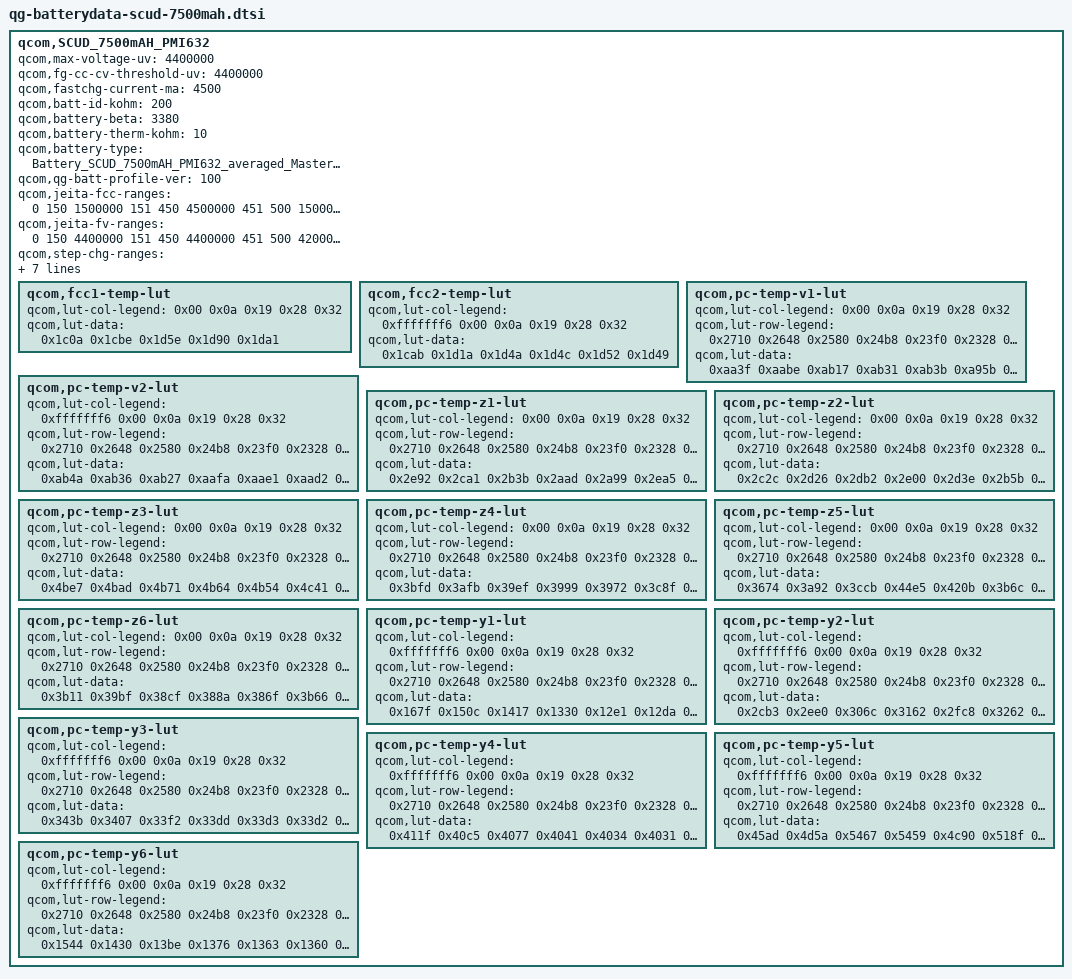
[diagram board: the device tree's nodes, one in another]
qcom,SCUD_7500mAH_PMI632 {
	qcom,max-voltage-uv = <4400000>;
	qcom,fg-cc-cv-threshold-uv = <4400000>;
	qcom,fastchg-current-ma = <4500>;
	qcom,batt-id-kohm = <200>;
	qcom,battery-beta = <3380>;
	qcom,battery-therm-kohm = <10>;
	qcom,battery-type = "Battery_SCUD_7500mAH_PMI632_averaged_MasterSlave_Jul21th2020";
	qcom,qg-batt-profile-ver = <100>;
	qcom,jeita-fcc-ranges = <0 150 1500000 151 450 4500000 451 500 1500000>;
	qcom,jeita-fv-ranges = <0 150 4400000 151 450 4400000 451 500 4200000>;
	qcom,step-chg-ranges = <3600000 3800000 4500000 3800001 4300000 4500000 4300001 4400000 2500000>;
	qcom,ocv-based-step-chg;
	qcom,jeita-soft-thresholds = <9556 4060>;
	qcom,jeita-hard-thresholds = <22733 8376>;
	qcom,jeita-soft-hys-thresholds = <20318 10563>;
	qcom,jeita-soft-fcc-ua = <4500000 4500000>;
	qcom,jeita-soft-fv-uv = <4400000 4400000>;

	qcom,fcc1-temp-lut {
		qcom,lut-col-legend = <0x00 0x0a 0x19 0x28 0x32>;
		qcom,lut-data = <0x1c0a 0x1cbe 0x1d5e 0x1d90 0x1da1>;
	};

	qcom,fcc2-temp-lut {
		qcom,lut-col-legend = <0xfffffff6 0x00 0x0a 0x19 0x28 0x32>;
		qcom,lut-data = <0x1cab 0x1d1a 0x1d4a 0x1d4c 0x1d52 0x1d49>;
	};

	qcom,pc-temp-v1-lut {
		qcom,lut-col-legend = <0x00 0x0a 0x19 0x28 0x32>;
		qcom,lut-row-legend = <0x2710 0x2648 0x2580 0x24b8 0x23f0 0x2328 0x2260 0x2198 0x20d0 0x2008 0x1f40 0x1e78 0x1db0 0x1ce8 0x1c20 0x1b58 0x1a90 0x19c8 0x1900 0x1838 0x1770 0x16a8 0x15e0 0x1518 0x1450 0x1388 0x12c0 0x11f8 0x1130 0x1068 0xfa0 0xed8 0xe10 0xd48 0xc80 0xbb8 0xaf0 0xa28 0x960 0x898 0x7d0 0x708 0x640 0x578 0x4b0 0x3e8 0x384 0x320 0x2bc 0x258 0x1f4 0x190 0x12c 0xc8 0x64 0x00>;
		qcom,lut-data = <0xaa3f 0xaabe 0xab17 0xab31 0xab3b 0xa95b 0xa9db 0xaa47 0xaa5d 0xaa67 0xa86b 0xa8f6 0xa960 0xa97f 0xa98b 0xa77c 0xa80e 0xa878 0xa89d 0xa8ad 0xa693 0xa726 0xa78c 0xa7b7 0xa7cb 0xa5ab 0xa63a 0xa69f 0xa6cd 0xa6e5 0xa4c8 0xa550 0xa5b5 0xa5e3 0xa5fe 0xa3e9 0xa468 0xa4cb 0xa4f8 0xa516 0xa30e 0xa386 0xa3e4 0xa410 0xa42f 0xa238 0xa2a7 0xa2fd 0xa32c 0xa349 0xa166 0xa1ce 0xa21b 0xa24c 0xa266 0xa09c 0xa0f9 0xa142 0xa170 0xa189 0x9fdd 0xa02c 0xa06d 0xa096 0xa0b1 0x9f23 0x9f69 0x9fa0 0x9fc5 0x9fe0 0x9e63 0x9eab 0x9ed8 0x9efa 0x9f12 0x9d9d 0x9def 0x9e18 0x9e37 0x9e4c 0x9ce5 0x9d38 0x9d62 0x9d7d 0x9d90 0x9c48 0x9c8a 0x9cb3 0x9ccb 0x9cde 0x9bb8 0x9bea 0x9c0e 0x9c1f 0x9c31 0x9b26 0x9b51 0x9b78 0x9b82 0x9b8f 0x9a91 0x9ab1 0x9ad6 0x9ae0 0x9ae9 0x99fd 0x9a11 0x9a06 0x9a10 0x9a23 0x996c 0x9965 0x9920 0x991b 0x993f 0x98dd 0x9890 0x985f 0x985a 0x987f 0x9851 0x97b8 0x97b5 0x97d4 0x97f0 0x97c3 0x972d 0x972f 0x9764 0x9775 0x973e 0x96cf 0x96d8 0x96fb 0x9702 0x96d8 0x9683 0x9695 0x969b 0x9698 0x9687 0x9641 0x964e 0x9641 0x9639 0x9642 0x9607 0x9605 0x95eb 0x95e3 0x9609 0x95d3 0x95c1 0x959e 0x9596 0x95d8 0x95a1 0x9583 0x9558 0x954e 0x95ad 0x9573 0x954c 0x951a 0x950b 0x9588 0x9547 0x9519 0x94e2 0x94cd 0x9566 0x951e 0x94eb 0x94b1 0x9496 0x9545 0x94f6 0x94bf 0x9480 0x945e 0x9525 0x94d2 0x9496 0x944c 0x941e 0x94fd 0x94a9 0x946d 0x9415 0x93da 0x94c2 0x9469 0x9430 0x93d0 0x938d 0x9474 0x940d 0x93d4 0x9377 0x9333 0x9414 0x93a5 0x9369 0x9311 0x92ce 0x9394 0x932e 0x92f4 0x92a0 0x925c 0x9304 0x92a6 0x926f 0x921e 0x91d9 0x9263 0x9201 0x91cf 0x917e 0x913a 0x91cf 0x916f 0x913e 0x90f4 0x90b1 0x9157 0x910e 0x90e1 0x90a0 0x9061 0x9134 0x90f1 0x90cb 0x9089 0x904d 0x911c 0x90da 0x90b7 0x907b 0x903e 0x90fc 0x90c4 0x90a7 0x9069 0x902b 0x90d6 0x909e 0x907e 0x903a 0x8ff7 0x9075 0x8fea 0x8fa8 0x8f47 0x8eeb 0x8f20 0x8e3b 0x8dfe 0x8d98 0x8d39 0x8d11 0x8bfd 0x8bc6 0x8b60 0x8b00 0x8a43 0x88d5 0x88c3 0x885b 0x87fd 0x8568 0x83b0 0x8418 0x83b8 0x835b 0x7530 0x7530 0x7530 0x7530 0x7530>;
	};

	qcom,pc-temp-v2-lut {
		qcom,lut-col-legend = <0xfffffff6 0x00 0x0a 0x19 0x28 0x32>;
		qcom,lut-row-legend = <0x2710 0x2648 0x2580 0x24b8 0x23f0 0x2328 0x2260 0x2198 0x20d0 0x2008 0x1f40 0x1e78 0x1db0 0x1ce8 0x1c20 0x1b58 0x1a90 0x19c8 0x1900 0x1838 0x1770 0x16a8 0x15e0 0x1518 0x1450 0x1388 0x12c0 0x11f8 0x1130 0x1068 0xfa0 0xed8 0xe10 0xd48 0xc80 0xbb8 0xaf0 0xa28 0x960 0x898 0x7d0 0x708 0x640 0x578 0x4b0 0x3e8 0x384 0x320 0x2bc 0x258 0x1f4 0x190 0x12c 0xc8 0x64 0x00>;
		qcom,lut-data = <0xab4a 0xab36 0xab27 0xaafa 0xaae1 0xaad2 0xa9fc 0xaa11 0xaa1a 0xa9ea 0xa9dd 0xa9d2 0xa8ca 0xa8fd 0xa917 0xa8e5 0xa8e0 0xa8d9 0xa7b8 0xa7fb 0xa81f 0xa7ed 0xa7ee 0xa7e9 0xa6c6 0xa70b 0xa733 0xa702 0xa706 0xa703 0xa5dc 0xa620 0xa649 0xa619 0xa61e 0xa61e 0xa4ed 0xa532 0xa55e 0xa52e 0xa535 0xa535 0xa400 0xa446 0xa473 0xa443 0xa44b 0xa44d 0xa318 0xa361 0xa38c 0xa35d 0xa366 0xa368 0xa235 0xa281 0xa2a9 0xa279 0xa283 0xa287 0xa157 0xa1a6 0xa1c8 0xa199 0xa1a4 0xa1a8 0xa082 0xa0ce 0xa0ed 0xa0bf 0xa0cc 0xa0cf 0x9fb2 0x9ffa 0xa016 0x9fe8 0x9ff8 0x9ffa 0x9ed4 0x9f2c 0x9f46 0x9f1c 0x9f2b 0x9f2e 0x9dd6 0x9e63 0x9e7c 0x9e55 0x9e62 0x9e67 0x9cd6 0x9d93 0x9db6 0x9d96 0x9da1 0x9da7 0x9bf2 0x9cab 0x9cf7 0x9cdf 0x9ce9 0x9cef 0x9b1f 0x9bb8 0x9c38 0x9c2e 0x9c38 0x9c3e 0x9a56 0x9ad8 0x9b67 0x9b81 0x9b8e 0x9b92 0x9996 0x9a09 0x9a7b 0x9adc 0x9aec 0x9af0 0x98df 0x9949 0x999d 0x9a28 0x9a3d 0x9a41 0x9833 0x9894 0x98d7 0x993f 0x995d 0x9964 0x9793 0x97ec 0x9824 0x984b 0x9873 0x987d 0x96f8 0x9755 0x9788 0x979a 0x97c3 0x97cd 0x965c 0x96cf 0x96fe 0x9712 0x9735 0x9741 0x95c8 0x9654 0x9683 0x969c 0x96bb 0x96c7 0x9553 0x95e0 0x9616 0x9632 0x9650 0x965c 0x94f2 0x9573 0x95b3 0x95d1 0x95f0 0x95fb 0x94a2 0x950f 0x9558 0x957a 0x9599 0x95a1 0x9464 0x94ad 0x9503 0x952a 0x9548 0x954f 0x9430 0x945a 0x94b4 0x94e1 0x94ff 0x9503 0x93fd 0x9418 0x9469 0x949a 0x94bc 0x94bd 0x93cb 0x93e2 0x9422 0x9458 0x947d 0x947b 0x9399 0x93b5 0x93e1 0x9419 0x943d 0x9437 0x9363 0x9395 0x93a5 0x93e1 0x93fe 0x93f3 0x932a 0x9373 0x936f 0x93a5 0x93b6 0x93a4 0x92ec 0x934a 0x9344 0x9361 0x935c 0x933c 0x92a9 0x931a 0x931b 0x9317 0x92f9 0x92c6 0x9261 0x92e0 0x92e6 0x92ce 0x92a1 0x9264 0x9212 0x9299 0x92a1 0x9286 0x9251 0x9213 0x91bb 0x9243 0x924d 0x9235 0x91fa 0x91bd 0x9161 0x91cf 0x91e1 0x91d1 0x9192 0x9155 0x9107 0x913d 0x9160 0x915b 0x911c 0x90df 0x90ab 0x90a2 0x90c2 0x90c3 0x9086 0x9048 0x904f 0x9012 0x903f 0x9050 0x901f 0x8fe6 0x8ff1 0x8fb6 0x8ff7 0x9022 0x8ffa 0x8fc5 0x8fbf 0x8f93 0x8fdb 0x9012 0x8fed 0x8fb7 0x8f88 0x8f66 0x8fbf 0x9004 0x8fdf 0x8fa7 0x8f4b 0x8f2f 0x8f91 0x8fe7 0x8fc4 0x8f8c 0x8f00 0x8ed8 0x8f3a 0x8fac 0x8f80 0x8f3b 0x8ea7 0x8e23 0x8e54 0x8ec9 0x8e7f 0x8e1b 0x8e01 0x8cc6 0x8c73 0x8d07 0x8cac 0x8c45 0x8ce1 0x8a7e 0x89e4 0x8aac 0x8a4a 0x89dd 0x8b04 0x86ff 0x866d 0x877c 0x870a 0x8695 0x87f4 0x816c 0x8106 0x82bf 0x8211 0x818d 0x8254 0x78cf 0x72f6 0x7258 0x72c5 0x7305>;
	};

	qcom,pc-temp-z1-lut {
		qcom,lut-col-legend = <0x00 0x0a 0x19 0x28 0x32>;
		qcom,lut-row-legend = <0x2710 0x2648 0x2580 0x24b8 0x23f0 0x2328 0x2260 0x2198 0x20d0 0x2008 0x1f40 0x1e78 0x1db0 0x1ce8 0x1c20 0x1b58 0x1a90 0x19c8 0x1900 0x1838 0x1770 0x16a8 0x15e0 0x1518 0x1450 0x1388 0x12c0 0x11f8 0x1130 0x1068 0xfa0 0xed8 0xe10 0xd48 0xc80 0xbb8 0xaf0 0xa28 0x960 0x898 0x7d0 0x708 0x640 0x578 0x4b0 0x3e8 0x384 0x320 0x2bc 0x258 0x1f4 0x190 0x12c 0xc8 0x64 0x00>;
		qcom,lut-data = <0x2e92 0x2ca1 0x2b3b 0x2aad 0x2a99 0x2ea5 0x2cad 0x2b35 0x2abd 0x2aad 0x2ea4 0x2cae 0x2b3b 0x2ac0 0x2ab2 0x2ea0 0x2caa 0x2b3c 0x2ac0 0x2ab6 0x2e90 0x2ca3 0x2b3b 0x2ac1 0x2ab7 0x2e79 0x2c9c 0x2b3a 0x2ac2 0x2ab8 0x2e71 0x2c92 0x2b38 0x2ac3 0x2ab9 0x2e71 0x2c8c 0x2b34 0x2ac3 0x2abc 0x2e72 0x2c86 0x2b33 0x2ac4 0x2abe 0x2e6a 0x2c81 0x2b34 0x2ac6 0x2ac0 0x2e5a 0x2c81 0x2b36 0x2ac8 0x2ac1 0x2e4f 0x2c82 0x2b36 0x2ac9 0x2ac2 0x2e4a 0x2c81 0x2b37 0x2ac9 0x2ac1 0x2e45 0x2c7f 0x2b37 0x2ac9 0x2ac1 0x2e40 0x2c7c 0x2b38 0x2aca 0x2ac3 0x2e3a 0x2c7a 0x2b39 0x2acc 0x2ac4 0x2e33 0x2c79 0x2b3a 0x2acc 0x2ac5 0x2e27 0x2c78 0x2b3b 0x2aca 0x2ac6 0x2e1a 0x2c7c 0x2b3d 0x2aca 0x2ac7 0x2e17 0x2c83 0x2b3f 0x2acc 0x2ac8 0x2e20 0x2c87 0x2b42 0x2ace 0x2aca 0x2e2a 0x2c8a 0x2b45 0x2ad0 0x2acb 0x2e2f 0x2c8c 0x2b47 0x2ad2 0x2acc 0x2e33 0x2c8e 0x2b4a 0x2ad3 0x2acd 0x2e37 0x2c91 0x2b4d 0x2ad5 0x2acf 0x2e34 0x2c92 0x2b51 0x2ad8 0x2ad2 0x2e2f 0x2c94 0x2b53 0x2ada 0x2ad4 0x2e32 0x2c95 0x2b56 0x2add 0x2ad6 0x2e3a 0x2c97 0x2b5a 0x2adf 0x2ad7 0x2e40 0x2c99 0x2b5d 0x2ae1 0x2ad9 0x2e41 0x2c9c 0x2b61 0x2ae3 0x2ada 0x2e3f 0x2ca8 0x2b62 0x2ae4 0x2adb 0x2e41 0x2cb2 0x2b64 0x2ae6 0x2add 0x2e4e 0x2cb5 0x2b67 0x2ae7 0x2ade 0x2e5c 0x2cb6 0x2b6b 0x2ae9 0x2adf 0x2e5e 0x2cb6 0x2b6e 0x2aeb 0x2ae1 0x2e59 0x2cb5 0x2b71 0x2aec 0x2ae2 0x2e58 0x2cb4 0x2b74 0x2aed 0x2ae4 0x2e5c 0x2cb8 0x2b77 0x2aef 0x2ae5 0x2e63 0x2cc4 0x2b7c 0x2af1 0x2ae6 0x2e6d 0x2cce 0x2b80 0x2af3 0x2ae7 0x2e7f 0x2cd9 0x2b82 0x2af5 0x2ae8 0x2e91 0x2ce1 0x2b84 0x2af7 0x2ae9 0x2eae 0x2ce4 0x2b88 0x2af8 0x2aea 0x2eb1 0x2cf1 0x2b8c 0x2af9 0x2aeb 0x2ea9 0x2ceb 0x2b91 0x2afc 0x2aeb 0x2e9d 0x2cf3 0x2b92 0x2afb 0x2aea 0x2e93 0x2cf3 0x2b90 0x2afc 0x2aeb 0x2ea7 0x2ce5 0x2b93 0x2afb 0x2aed 0x2e91 0x2ce8 0x2b96 0x2afd 0x2aed 0x2eac 0x2cf6 0x2b9d 0x2aff 0x2aee 0x2ec7 0x2cfb 0x2ba0 0x2b03 0x2af3 0x2eae 0x2d1c 0x2ba9 0x2b09 0x2af8 0x2ee8 0x2d25 0x2bb9 0x2b11 0x2b00 0x2ee8 0x2d25 0x2bb9 0x2b11 0x2b00 0x2ee8 0x2d25 0x2bb9 0x2b11 0x2b00>;
	};

	qcom,pc-temp-z2-lut {
		qcom,lut-col-legend = <0x00 0x0a 0x19 0x28 0x32>;
		qcom,lut-row-legend = <0x2710 0x2648 0x2580 0x24b8 0x23f0 0x2328 0x2260 0x2198 0x20d0 0x2008 0x1f40 0x1e78 0x1db0 0x1ce8 0x1c20 0x1b58 0x1a90 0x19c8 0x1900 0x1838 0x1770 0x16a8 0x15e0 0x1518 0x1450 0x1388 0x12c0 0x11f8 0x1130 0x1068 0xfa0 0xed8 0xe10 0xd48 0xc80 0xbb8 0xaf0 0xa28 0x960 0x898 0x7d0 0x708 0x640 0x578 0x4b0 0x3e8 0x384 0x320 0x2bc 0x258 0x1f4 0x190 0x12c 0xc8 0x64 0x00>;
		qcom,lut-data = <0x2c2c 0x2d26 0x2db2 0x2e00 0x2d3e 0x2b5b 0x2cc6 0x2d0f 0x2d7f 0x2d81 0x2b38 0x2c7f 0x2d90 0x2e14 0x2d93 0x2b27 0x2c3f 0x2db6 0x2e78 0x2da8 0x2b16 0x2c0c 0x2d92 0x2e79 0x2dd6 0x2b09 0x2bea 0x2d63 0x2e71 0x2e12 0x2b07 0x2bd0 0x2d38 0x2e58 0x2e01 0x2b0a 0x2bbe 0x2d0d 0x2e11 0x2dc6 0x2b0d 0x2bb0 0x2d04 0x2dca 0x2d8b 0x2b0c 0x2ba8 0x2d11 0x2d8b 0x2d4a 0x2b07 0x2baa 0x2d24 0x2d53 0x2d0d 0x2b03 0x2bb0 0x2d43 0x2d34 0x2cf9 0x2b01 0x2bba 0x2d6b 0x2d27 0x2cd9 0x2aff 0x2bce 0x2d78 0x2d28 0x2ccc 0x2afc 0x2bea 0x2d7a 0x2d22 0x2ce5 0x2af5 0x2c09 0x2d7c 0x2d1d 0x2d0d 0x2af2 0x2c2e 0x2d96 0x2d2f 0x2d3c 0x2b07 0x2c47 0x2dc9 0x2d4d 0x2d7a 0x2b2e 0x2c51 0x2dde 0x2d61 0x2da0 0x2b3b 0x2c5a 0x2de5 0x2d73 0x2d9b 0x2b3b 0x2c6e 0x2df0 0x2d90 0x2d91 0x2b3c 0x2c9a 0x2e3c 0x2e12 0x2dac 0x2b4a 0x2cc7 0x2eb7 0x2f30 0x2df5 0x2b78 0x2cf2 0x2ec3 0x2f95 0x2e43 0x2ba2 0x2d17 0x2e41 0x2ed1 0x2ea8 0x2bc5 0x2d1a 0x2dde 0x2e09 0x2ef6 0x2be1 0x2cfe 0x2de3 0x2e62 0x2eee 0x2bec 0x2ce6 0x2df0 0x2f68 0x2eb6 0x2bf1 0x2ce0 0x2e0c 0x2fb7 0x2e5f 0x2bf6 0x2cdc 0x2e67 0x2ee9 0x2d73 0x2bfb 0x2cdd 0x2ea5 0x2e1e 0x2ca7 0x2c02 0x2cee 0x2e74 0x2dfe 0x2cb0 0x2c08 0x2d01 0x2e20 0x2dee 0x2cee 0x2c0d 0x2d0b 0x2e0e 0x2dee 0x2d32 0x2c12 0x2d13 0x2e1e 0x2e24 0x2d7a 0x2c19 0x2d19 0x2e34 0x2e7a 0x2dd7 0x2c24 0x2d1f 0x2e51 0x2f03 0x2e7c 0x2c2e 0x2d26 0x2e79 0x2fbf 0x2f50 0x2c36 0x2d33 0x2eac 0x3024 0x2f91 0x2c3d 0x2d45 0x2efa 0x305f 0x2f93 0x2c40 0x2d4c 0x2f26 0x307b 0x2f96 0x2c3f 0x2d42 0x2f13 0x305a 0x2faa 0x2c43 0x2d3c 0x2efe 0x301b 0x2fc2 0x2c6a 0x2d41 0x2f0c 0x2feb 0x2fd1 0x2e40 0x2de9 0x2f43 0x2fb1 0x2fa4 0x2e70 0x2e3a 0x2f49 0x2f92 0x2f6a 0x2e5a 0x2e8b 0x2f27 0x2fae 0x2f80 0x2df8 0x2f04 0x2f1b 0x2f52 0x2f26 0x2d80 0x315a 0x2f3f 0x2f7d 0x2f7d 0x2d30 0x320b 0x2efd 0x3032 0x30bc 0x2cfe 0x2fce 0x3056 0x3005 0x2e8a 0x2c7d 0x2fca 0x3086 0x2eb0 0x2d28 0x2b27 0x2f28 0x3083 0x2dfa 0x2ccd 0x2a2c 0x2d18 0x3073 0x2d4f 0x2c68 0x2a2c 0x2d18 0x3073 0x2d4f 0x2c68 0x2a2c 0x2d18 0x3073 0x2d4f 0x2c68>;
	};

	qcom,pc-temp-z3-lut {
		qcom,lut-col-legend = <0x00 0x0a 0x19 0x28 0x32>;
		qcom,lut-row-legend = <0x2710 0x2648 0x2580 0x24b8 0x23f0 0x2328 0x2260 0x2198 0x20d0 0x2008 0x1f40 0x1e78 0x1db0 0x1ce8 0x1c20 0x1b58 0x1a90 0x19c8 0x1900 0x1838 0x1770 0x16a8 0x15e0 0x1518 0x1450 0x1388 0x12c0 0x11f8 0x1130 0x1068 0xfa0 0xed8 0xe10 0xd48 0xc80 0xbb8 0xaf0 0xa28 0x960 0x898 0x7d0 0x708 0x640 0x578 0x4b0 0x3e8 0x384 0x320 0x2bc 0x258 0x1f4 0x190 0x12c 0xc8 0x64 0x00>;
		qcom,lut-data = <0x4be7 0x4bad 0x4b71 0x4b64 0x4b54 0x4c41 0x4beb 0x4b99 0x4b6c 0x4b62 0x4c75 0x4c03 0x4bad 0x4b7b 0x4b6d 0x4c8d 0x4c0c 0x4bb7 0x4b87 0x4b77 0x4c93 0x4c10 0x4bbf 0x4b8d 0x4b7c 0x4c97 0x4c13 0x4bc2 0x4b91 0x4b7f 0x4c97 0x4c15 0x4bc0 0x4b92 0x4b7f 0x4c93 0x4c16 0x4bba 0x4b92 0x4b7f 0x4c8f 0x4c14 0x4bb6 0x4b92 0x4b7e 0x4c8d 0x4c12 0x4bb4 0x4b8c 0x4b7c 0x4c8a 0x4c10 0x4bb2 0x4b83 0x4b79 0x4c87 0x4c0e 0x4bad 0x4b7f 0x4b76 0x4c83 0x4c0a 0x4ba6 0x4b7c 0x4b71 0x4c7e 0x4c07 0x4ba2 0x4b7a 0x4b6e 0x4c79 0x4c02 0x4b9e 0x4b77 0x4b6c 0x4c75 0x4bfc 0x4b9c 0x4b73 0x4b6b 0x4c72 0x4bf5 0x4b9b 0x4b71 0x4b69 0x4c6f 0x4bf1 0x4b9b 0x4b70 0x4b65 0x4c6b 0x4bf0 0x4b9a 0x4b6f 0x4b63 0x4c6b 0x4bef 0x4b98 0x4b6f 0x4b64 0x4c6d 0x4bef 0x4b96 0x4b6f 0x4b65 0x4c6f 0x4bf0 0x4b9e 0x4b71 0x4b67 0x4c6e 0x4bf1 0x4bad 0x4b79 0x4b69 0x4c6b 0x4bf9 0x4bb0 0x4b7c 0x4b6a 0x4c69 0x4c04 0x4baa 0x4b70 0x4b64 0x4c6c 0x4c06 0x4ba2 0x4b65 0x4b5d 0x4c6f 0x4c01 0x4b9a 0x4b69 0x4b64 0x4c6f 0x4bfc 0x4b92 0x4b77 0x4b7b 0x4c6d 0x4bf8 0x4b92 0x4b80 0x4b84 0x4c69 0x4bf4 0x4b9b 0x4b84 0x4b7e 0x4c66 0x4bf2 0x4ba3 0x4b86 0x4b77 0x4c63 0x4bf0 0x4ba6 0x4b85 0x4b73 0x4c60 0x4bee 0x4ba9 0x4b81 0x4b70 0x4c5c 0x4bed 0x4ba9 0x4b7d 0x4b6c 0x4c59 0x4bed 0x4ba6 0x4b78 0x4b68 0x4c55 0x4bec 0x4ba2 0x4b75 0x4b65 0x4c52 0x4beb 0x4b9f 0x4b73 0x4b65 0x4c4e 0x4be9 0x4b9c 0x4b72 0x4b66 0x4c49 0x4be7 0x4b9a 0x4b72 0x4b66 0x4c44 0x4be5 0x4b98 0x4b72 0x4b66 0x4c3f 0x4be2 0x4b96 0x4b71 0x4b66 0x4c39 0x4bde 0x4b95 0x4b70 0x4b65 0x4c32 0x4bda 0x4b94 0x4b6e 0x4b63 0x4c28 0x4bd4 0x4b91 0x4b6e 0x4b65 0x4be2 0x4bc0 0x4b89 0x4b6b 0x4b65 0x4bd8 0x4bb1 0x4b85 0x4b68 0x4b61 0x4bb4 0x4ba6 0x4b82 0x4b67 0x4b5e 0x4b61 0x4b99 0x4b81 0x4b63 0x4b5c 0x4b5a 0x4b6a 0x4b77 0x4b61 0x4b5a 0x4b58 0x4b5e 0x4b77 0x4b5d 0x4b54 0x4b56 0x4b8c 0x4b6e 0x4b61 0x4b66 0x4b5d 0x4b7a 0x4b65 0x4b68 0x4b6a 0x4b61 0x4b6e 0x4b64 0x4b69 0x4b6c 0x4b7a 0x4bb4 0x4b5c 0x4b6b 0x4b66 0x4b7a 0x4bb4 0x4b5c 0x4b6b 0x4b66 0x4b7a 0x4bb4 0x4b5c 0x4b6b 0x4b66>;
	};

	qcom,pc-temp-z4-lut {
		qcom,lut-col-legend = <0x00 0x0a 0x19 0x28 0x32>;
		qcom,lut-row-legend = <0x2710 0x2648 0x2580 0x24b8 0x23f0 0x2328 0x2260 0x2198 0x20d0 0x2008 0x1f40 0x1e78 0x1db0 0x1ce8 0x1c20 0x1b58 0x1a90 0x19c8 0x1900 0x1838 0x1770 0x16a8 0x15e0 0x1518 0x1450 0x1388 0x12c0 0x11f8 0x1130 0x1068 0xfa0 0xed8 0xe10 0xd48 0xc80 0xbb8 0xaf0 0xa28 0x960 0x898 0x7d0 0x708 0x640 0x578 0x4b0 0x3e8 0x384 0x320 0x2bc 0x258 0x1f4 0x190 0x12c 0xc8 0x64 0x00>;
		qcom,lut-data = <0x3bfd 0x3afb 0x39ef 0x3999 0x3972 0x3c8f 0x3aeb 0x3a1f 0x39b1 0x398b 0x3c37 0x3acd 0x3a09 0x39aa 0x3989 0x3bd6 0x3a92 0x39f0 0x39a0 0x3986 0x3b87 0x3a55 0x39d0 0x3992 0x397d 0x3b3b 0x3a2c 0x39b3 0x3980 0x396f 0x3afc 0x3a08 0x39a1 0x3971 0x3964 0x3ac8 0x39eb 0x3993 0x3965 0x395b 0x3a9b 0x39d4 0x3984 0x395c 0x3953 0x3a75 0x39bf 0x3973 0x3956 0x394b 0x3a53 0x39ad 0x3967 0x3953 0x3945 0x3a36 0x399c 0x3962 0x394e 0x3942 0x3a1b 0x398f 0x3960 0x3949 0x393f 0x3a06 0x3983 0x395c 0x3945 0x393d 0x39fa 0x397b 0x3958 0x3941 0x3938 0x39f4 0x3979 0x3953 0x393e 0x3933 0x39ec 0x3978 0x394e 0x393a 0x392f 0x39d7 0x3977 0x3947 0x3935 0x392c 0x39ba 0x396f 0x3945 0x3932 0x392a 0x39a8 0x3965 0x3943 0x3930 0x3928 0x399e 0x3964 0x3943 0x392f 0x3927 0x3998 0x3968 0x394d 0x393b 0x3932 0x399a 0x396f 0x3967 0x3964 0x3959 0x39a4 0x3989 0x397f 0x397f 0x3971 0x39af 0x39ac 0x399b 0x398e 0x397a 0x39bc 0x39b3 0x39ab 0x3996 0x397f 0x39c8 0x39b3 0x39a8 0x398d 0x3973 0x39cd 0x39b2 0x39a0 0x3971 0x3950 0x39d0 0x39ad 0x3995 0x395c 0x393d 0x39d1 0x39a4 0x3982 0x394c 0x393a 0x39d0 0x399c 0x3970 0x3941 0x3938 0x39cb 0x3994 0x3963 0x393b 0x3933 0x39c5 0x398d 0x3959 0x3936 0x392e 0x39bf 0x3986 0x3954 0x3935 0x392d 0x39b8 0x397f 0x3951 0x3935 0x392d 0x39b0 0x3979 0x3950 0x3935 0x392d 0x39a7 0x3973 0x3950 0x3937 0x392f 0x399e 0x396e 0x3950 0x393b 0x3935 0x3995 0x396c 0x3952 0x393f 0x3939 0x398b 0x396b 0x3959 0x3946 0x393d 0x3983 0x3969 0x395d 0x394a 0x393f 0x397d 0x3960 0x3958 0x3948 0x393d 0x3973 0x3957 0x3950 0x3944 0x393b 0x3964 0x3951 0x394e 0x3946 0x393d 0x3964 0x3941 0x3943 0x3942 0x393a 0x3961 0x393c 0x3937 0x3936 0x3930 0x3989 0x3941 0x392e 0x392e 0x392b 0x39e0 0x3947 0x3926 0x3926 0x3921 0x39e3 0x3977 0x3925 0x391b 0x3917 0x39e0 0x3981 0x3923 0x391e 0x391b 0x39dd 0x394e 0x393d 0x392d 0x391c 0x39de 0x396e 0x394c 0x3929 0x391b 0x39e6 0x3980 0x394e 0x3928 0x3919 0x39e0 0x3943 0x3959 0x3926 0x391f 0x39e0 0x3943 0x3959 0x3926 0x391f 0x39e0 0x3943 0x3959 0x3926 0x391f>;
	};

	qcom,pc-temp-z5-lut {
		qcom,lut-col-legend = <0x00 0x0a 0x19 0x28 0x32>;
		qcom,lut-row-legend = <0x2710 0x2648 0x2580 0x24b8 0x23f0 0x2328 0x2260 0x2198 0x20d0 0x2008 0x1f40 0x1e78 0x1db0 0x1ce8 0x1c20 0x1b58 0x1a90 0x19c8 0x1900 0x1838 0x1770 0x16a8 0x15e0 0x1518 0x1450 0x1388 0x12c0 0x11f8 0x1130 0x1068 0xfa0 0xed8 0xe10 0xd48 0xc80 0xbb8 0xaf0 0xa28 0x960 0x898 0x7d0 0x708 0x640 0x578 0x4b0 0x3e8 0x384 0x320 0x2bc 0x258 0x1f4 0x190 0x12c 0xc8 0x64 0x00>;
		qcom,lut-data = <0x3674 0x3a92 0x3ccb 0x44e5 0x420b 0x3b6c 0x443e 0x47d4 0x48cf 0x4a08 0x3fb7 0x48cc 0x4f4f 0x51f1 0x5435 0x4318 0x4a99 0x54bd 0x5a5a 0x5e03 0x4574 0x4c1f 0x59a6 0x5fa3 0x626d 0x4761 0x4e50 0x5c4b 0x63d2 0x6609 0x496d 0x50d9 0x5b6a 0x6707 0x677e 0x4b89 0x5371 0x5985 0x69ce 0x682f 0x4dc4 0x55fe 0x599c 0x6ad7 0x68a4 0x5062 0x58d0 0x5ef5 0x671c 0x6a7f 0x5353 0x5c44 0x6351 0x6198 0x6d32 0x55e6 0x6065 0x6203 0x5ff7 0x6cb0 0x57ef 0x6519 0x5f5b 0x619b 0x6748 0x59d3 0x6c2a 0x5ed5 0x62f3 0x63ee 0x5bd2 0x71d3 0x6072 0x615c 0x6782 0x5dd8 0x70d1 0x6305 0x5f9b 0x6cab 0x605f 0x6b8f 0x684c 0x6179 0x6cfd 0x6472 0x68fd 0x705b 0x6632 0x6adc 0x6acc 0x74d6 0x74e4 0x6bcf 0x69ea 0x746a 0x884a 0x77ad 0x719f 0x76a2 0x8a92 0x94f3 0x7c32 0x7964 0x8647 0xa199 0x9dab 0xacd5 0x8b0f 0x877f 0xacdc 0xa959 0xffff 0xa89c 0x84f6 0xb420 0xca0f 0xffff 0xb12a 0x8017 0xbcbd 0xf024 0xd825 0x829c 0x64cc 0xcca6 0xf3ad 0x9f28 0x5318 0x4851 0xdb97 0xd834 0x7fe4 0x5185 0x4f63 0xdd0f 0xbcc4 0x68b5 0x563a 0x6b2a 0xd5cb 0xae29 0x6512 0x5c3e 0x769b 0xcd5a 0xa333 0x6ba8 0x69a9 0x746d 0xc733 0xa080 0x756a 0x78f7 0x7246 0xc16c 0xa048 0x8368 0x8519 0x7548 0xbc45 0xa046 0x954a 0x9068 0x7d8a 0xb74c 0xa39f 0xa390 0x96cd 0x83e6 0xb354 0xac4c 0xb0e7 0x9a3c 0x8878 0xb110 0xb35a 0xb7a4 0x9ca1 0x8bc3 0xaf5f 0xba20 0xb6dc 0x9f18 0x8e18 0xaeb2 0xbf35 0xb4a9 0xa17c 0x906d 0xaef8 0xc06e 0xb062 0xa05d 0x8fc1 0xaf66 0xc0c5 0xa4f3 0x9092 0x8417 0xaec9 0xbfe6 0x9c8a 0x8048 0x772f 0xaa35 0xb915 0x9b58 0x79cd 0x704d 0xa642 0xafb6 0x9a21 0x7508 0x6b99 0xa37d 0xa563 0x8d9e 0x6ed3 0x691a 0x7370 0x9b43 0x8de9 0x6d62 0x69c4 0x6a66 0x8262 0x90ba 0x6d7b 0x6709 0x55b2 0x6aa6 0x89ce 0x7286 0x636d 0x3507 0x585f 0x8e49 0x71d4 0x6b6c 0x33e9 0x3b74 0x7017 0x83c3 0x8223 0x3395 0x38c0 0x762c 0x7556 0x678b 0x3397 0x50db 0x56be 0x577e 0x76b2 0x347a 0x4363 0x44f5 0x5b08 0x78bc 0x33e9 0x3c31 0x423c 0x5962 0x79a2 0x3888 0x71d3 0x3c2f 0x59e7 0x61be 0x3888 0x71d3 0x3c2f 0x59e7 0x61be 0x3888 0x71d3 0x3c2f 0x59e7 0x61be>;
	};

	qcom,pc-temp-z6-lut {
		qcom,lut-col-legend = <0x00 0x0a 0x19 0x28 0x32>;
		qcom,lut-row-legend = <0x2710 0x2648 0x2580 0x24b8 0x23f0 0x2328 0x2260 0x2198 0x20d0 0x2008 0x1f40 0x1e78 0x1db0 0x1ce8 0x1c20 0x1b58 0x1a90 0x19c8 0x1900 0x1838 0x1770 0x16a8 0x15e0 0x1518 0x1450 0x1388 0x12c0 0x11f8 0x1130 0x1068 0xfa0 0xed8 0xe10 0xd48 0xc80 0xbb8 0xaf0 0xa28 0x960 0x898 0x7d0 0x708 0x640 0x578 0x4b0 0x3e8 0x384 0x320 0x2bc 0x258 0x1f4 0x190 0x12c 0xc8 0x64 0x00>;
		qcom,lut-data = <0x3b11 0x39bf 0x38cf 0x388a 0x386f 0x3b66 0x39d4 0x38f4 0x389c 0x3884 0x3b53 0x39d5 0x38f8 0x38a2 0x388a 0x3b39 0x39bd 0x38f7 0x38a4 0x388e 0x3b17 0x39a1 0x38ed 0x38a1 0x388d 0x3aee 0x398e 0x38e0 0x389c 0x388a 0x3acb 0x397e 0x38d7 0x3897 0x3887 0x3aae 0x396f 0x38ce 0x3893 0x3883 0x3a94 0x3962 0x38c5 0x388e 0x387f 0x3a7d 0x3957 0x38be 0x3888 0x387b 0x3a69 0x394d 0x38b7 0x3882 0x3877 0x3a57 0x3943 0x38b2 0x387e 0x3874 0x3a47 0x393b 0x38ad 0x387a 0x3870 0x3a39 0x3934 0x38a9 0x3877 0x386d 0x3a2e 0x392e 0x38a6 0x3874 0x386a 0x3a27 0x392a 0x38a3 0x3871 0x3867 0x3a1f 0x3926 0x38a0 0x386e 0x3864 0x3a11 0x3923 0x389d 0x386b 0x3861 0x3a03 0x391f 0x389c 0x3869 0x3860 0x39fd 0x391c 0x389a 0x3868 0x385f 0x39fc 0x391c 0x3899 0x3868 0x385f 0x39fb 0x391f 0x38a2 0x3870 0x3865 0x39fd 0x3924 0x38b5 0x3887 0x3878 0x3a02 0x3934 0x38c2 0x3891 0x3881 0x3a08 0x394a 0x38ca 0x3891 0x3882 0x3a0f 0x394e 0x38cf 0x3891 0x3883 0x3a17 0x394d 0x38cb 0x388f 0x3882 0x3a1a 0x394a 0x38c3 0x388b 0x387f 0x3a1c 0x3947 0x38bf 0x3888 0x387c 0x3a1d 0x3942 0x38bc 0x3884 0x3878 0x3a1c 0x393e 0x38b9 0x3880 0x3873 0x3a19 0x393b 0x38b6 0x387d 0x386f 0x3a16 0x3937 0x38b3 0x3879 0x386c 0x3a13 0x3935 0x38b0 0x3876 0x3869 0x3a10 0x3933 0x38ae 0x3874 0x3867 0x3a0e 0x3931 0x38ad 0x3872 0x3865 0x3a0b 0x392f 0x38ab 0x3872 0x3866 0x3a09 0x392e 0x38aa 0x3874 0x3868 0x3a07 0x392e 0x38ab 0x3875 0x386a 0x3a05 0x392e 0x38ad 0x3878 0x386c 0x3a04 0x392e 0x38af 0x387a 0x386d 0x3a03 0x392b 0x38ad 0x3878 0x386c 0x3a01 0x3928 0x38aa 0x3876 0x386a 0x39fe 0x3925 0x38a8 0x3877 0x386c 0x39e5 0x3918 0x38a1 0x3874 0x386b 0x39e3 0x3910 0x389a 0x386d 0x3865 0x39e2 0x390e 0x3895 0x386a 0x3861 0x39df 0x390b 0x3891 0x3864 0x385c 0x39de 0x3908 0x388c 0x385e 0x3856 0x39df 0x3908 0x388b 0x385d 0x3855 0x39e2 0x390e 0x3893 0x3867 0x3860 0x39ee 0x3916 0x3897 0x386a 0x3862 0x39fc 0x391e 0x389a 0x386b 0x3864 0x3a12 0x3930 0x389d 0x386d 0x3865 0x3a12 0x3930 0x389d 0x386d 0x3865 0x3a12 0x3930 0x389d 0x386d 0x3865>;
	};

	qcom,pc-temp-y1-lut {
		qcom,lut-col-legend = <0xfffffff6 0x00 0x0a 0x19 0x28 0x32>;
		qcom,lut-row-legend = <0x2710 0x2648 0x2580 0x24b8 0x23f0 0x2328 0x2260 0x2198 0x20d0 0x2008 0x1f40 0x1e78 0x1db0 0x1ce8 0x1c20 0x1b58 0x1a90 0x19c8 0x1900 0x1838 0x1770 0x16a8 0x15e0 0x1518 0x1450 0x1388 0x12c0 0x11f8 0x1130 0x1068 0xfa0 0xed8 0xe10 0xd48 0xc80 0xbb8 0xaf0 0xa28 0x960 0x898 0x7d0 0x708 0x640 0x578 0x4b0 0x3e8 0x384 0x320 0x2bc 0x258 0x1f4 0x190 0x12c 0xc8 0x64 0x00>;
		qcom,lut-data = <0x167f 0x150c 0x1417 0x1330 0x12e1 0x12da 0x168f 0x1514 0x1414 0x132f 0x12e0 0x12da 0x169a 0x1518 0x1411 0x132d 0x12e0 0x12d9 0x16a1 0x151b 0x140e 0x132c 0x12df 0x12d8 0x16a4 0x151b 0x140b 0x132a 0x12de 0x12d7 0x16a4 0x151b 0x1408 0x1329 0x12de 0x12d6 0x169f 0x1515 0x1406 0x1327 0x12dd 0x12d6 0x1696 0x1509 0x1403 0x1325 0x12dc 0x12d6 0x1692 0x1507 0x13ff 0x1324 0x12dc 0x12d6 0x1697 0x150c 0x13f9 0x1323 0x12dc 0x12d5 0x169a 0x150f 0x13f5 0x1323 0x12dc 0x12d4 0x1693 0x150e 0x13f6 0x1323 0x12dc 0x12d5 0x1685 0x150c 0x13f7 0x1322 0x12dd 0x12d7 0x167e 0x150a 0x13f8 0x1322 0x12dd 0x12d8 0x1684 0x1505 0x13f7 0x1322 0x12de 0x12d8 0x168b 0x1502 0x13f6 0x1323 0x12de 0x12d9 0x168c 0x1507 0x13f6 0x1323 0x12df 0x12d8 0x168b 0x150f 0x13f6 0x1324 0x12e0 0x12d8 0x168a 0x1510 0x13f6 0x1325 0x12e0 0x12d8 0x168c 0x150d 0x13f6 0x1325 0x12e1 0x12d9 0x168e 0x150a 0x13f5 0x1326 0x12e2 0x12da 0x168f 0x150a 0x13f5 0x1328 0x12e2 0x12db 0x1690 0x150a 0x13f6 0x132a 0x12e2 0x12dc 0x168f 0x150a 0x13f7 0x132c 0x12e2 0x12dd 0x1686 0x1509 0x13fb 0x132e 0x12e3 0x12dd 0x167a 0x1509 0x13ff 0x1330 0x12e4 0x12de 0x1679 0x150d 0x1400 0x1332 0x12e6 0x12de 0x1684 0x1515 0x1401 0x1335 0x12e7 0x12df 0x168c 0x1519 0x1403 0x1337 0x12e8 0x12e0 0x168a 0x151b 0x1406 0x1339 0x12ea 0x12e1 0x1688 0x151d 0x1409 0x133b 0x12eb 0x12e2 0x1687 0x151e 0x140b 0x133e 0x12ed 0x12e4 0x1685 0x151f 0x140e 0x1342 0x12ee 0x12e6 0x1684 0x1520 0x1410 0x1345 0x12f0 0x12e7 0x1688 0x1522 0x1413 0x1347 0x12f1 0x12e7 0x1690 0x1523 0x1414 0x1348 0x12f2 0x12e7 0x1695 0x1521 0x1416 0x134a 0x12f3 0x12e8 0x169e 0x151d 0x1419 0x134b 0x12f4 0x12ea 0x16a6 0x151c 0x141b 0x134d 0x12f5 0x12eb 0x16a4 0x151f 0x141e 0x134f 0x12f6 0x12ec 0x169d 0x1523 0x1420 0x1351 0x12f7 0x12ed 0x1697 0x1528 0x1421 0x1352 0x12f8 0x12ee 0x1696 0x1533 0x1422 0x1352 0x12f8 0x12ef 0x1696 0x152d 0x1430 0x1354 0x12f9 0x12ef 0x1693 0x1525 0x1432 0x1355 0x12f9 0x12f0 0x1694 0x1538 0x1430 0x1359 0x12fb 0x12f1 0x1693 0x1530 0x142c 0x135c 0x12fa 0x12f0 0x1694 0x152e 0x143d 0x135c 0x12fc 0x12f2 0x16ae 0x1535 0x1438 0x135e 0x12fc 0x12f1 0x169a 0x1539 0x1436 0x135f 0x12fc 0x12f2 0x16bd 0x153f 0x143a 0x135f 0x12fc 0x12f2 0x16d7 0x1554 0x1447 0x1366 0x12ff 0x12f5 0x171c 0x1595 0x144e 0x136e 0x1301 0x12f9 0x1774 0x160e 0x146f 0x1376 0x1308 0x12fb 0x1774 0x160e 0x146f 0x1376 0x1308 0x12fb 0x1774 0x160e 0x146f 0x1376 0x1308 0x12fb>;
	};

	qcom,pc-temp-y2-lut {
		qcom,lut-col-legend = <0xfffffff6 0x00 0x0a 0x19 0x28 0x32>;
		qcom,lut-row-legend = <0x2710 0x2648 0x2580 0x24b8 0x23f0 0x2328 0x2260 0x2198 0x20d0 0x2008 0x1f40 0x1e78 0x1db0 0x1ce8 0x1c20 0x1b58 0x1a90 0x19c8 0x1900 0x1838 0x1770 0x16a8 0x15e0 0x1518 0x1450 0x1388 0x12c0 0x11f8 0x1130 0x1068 0xfa0 0xed8 0xe10 0xd48 0xc80 0xbb8 0xaf0 0xa28 0x960 0x898 0x7d0 0x708 0x640 0x578 0x4b0 0x3e8 0x384 0x320 0x2bc 0x258 0x1f4 0x190 0x12c 0xc8 0x64 0x00>;
		qcom,lut-data = <0x2cb3 0x2ee0 0x306c 0x3162 0x2fc8 0x3262 0x2ca5 0x2e99 0x3008 0x3151 0x3016 0x31d3 0x2c99 0x2e45 0x2fa4 0x3116 0x303f 0x311c 0x2c90 0x2df0 0x2f46 0x30c6 0x304c 0x305f 0x2c8a 0x2daa 0x2ef4 0x3076 0x3046 0x2fc0 0x2c88 0x2d7e 0x2eb5 0x303d 0x3036 0x2f63 0x2c8b 0x2d69 0x2e84 0x3006 0x3001 0x2f37 0x2c92 0x2d5c 0x2e5d 0x2fcd 0x2fb4 0x2f1a 0x2c93 0x2d59 0x2e47 0x2fb5 0x2f8a 0x2f15 0x2c87 0x2d5b 0x2e38 0x2f9e 0x2f71 0x2f0e 0x2c7c 0x2d5f 0x2e31 0x2f8e 0x2f57 0x2f0d 0x2cbb 0x2d66 0x2e3f 0x2f79 0x2f2c 0x2f21 0x2d57 0x2d76 0x2e5a 0x2f60 0x2f02 0x2f37 0x2d92 0x2d99 0x2e6d 0x2f6f 0x2f05 0x2f36 0x2d4f 0x2e01 0x2e7f 0x2fab 0x2f41 0x2f23 0x2d06 0x2e4c 0x2e95 0x2fe5 0x2f87 0x2f16 0x2d1d 0x2e49 0x2ed1 0x300c 0x2fc6 0x2f33 0x2d7d 0x2e40 0x2f20 0x3037 0x3011 0x2f5d 0x2db5 0x2e43 0x2f3f 0x307a 0x3085 0x2f76 0x2dbc 0x2e66 0x2f4b 0x30e9 0x3143 0x2fe4 0x2dc1 0x2e95 0x2f5a 0x3126 0x31ac 0x3032 0x2dc9 0x2ec1 0x2f84 0x3112 0x319a 0x304a 0x2dd5 0x2ef0 0x2fc6 0x30f3 0x317a 0x307b 0x2dda 0x2f11 0x3001 0x30fb 0x317b 0x30af 0x2dd1 0x2f2a 0x3043 0x3145 0x3192 0x30fe 0x2db8 0x2f3e 0x3063 0x317d 0x31b0 0x314c 0x2d4d 0x2f53 0x305d 0x3188 0x31de 0x3192 0x2b7f 0x2f66 0x3054 0x318f 0x3212 0x31df 0x2a21 0x2f72 0x3054 0x31a4 0x323a 0x3232 0x2908 0x2f7b 0x305f 0x31d7 0x326b 0x3298 0x26fd 0x2f81 0x3065 0x31f7 0x3295 0x32da 0x263b 0x2f86 0x303e 0x3202 0x331a 0x32da 0x2619 0x2f8c 0x3005 0x320d 0x33c0 0x32ca 0x2604 0x2f87 0x3004 0x3206 0x33cc 0x32e4 0x25f2 0x2f29 0x3033 0x31dd 0x336a 0x333a 0x25e4 0x2ea7 0x3051 0x31b5 0x3304 0x3377 0x25db 0x2e45 0x3031 0x3196 0x32ab 0x3356 0x25d4 0x2de6 0x2fee 0x3176 0x3264 0x3319 0x25cf 0x2d7d 0x2fb3 0x3166 0x3253 0x3310 0x25cc 0x2d0f 0x2f7a 0x316d 0x323b 0x3302 0x25c9 0x2c83 0x2f36 0x3177 0x3226 0x32d7 0x25c7 0x2b23 0x2ed7 0x3190 0x322d 0x3215 0x25c5 0x2920 0x2e64 0x3196 0x3231 0x3175 0x25c4 0x277d 0x2de6 0x3153 0x32a8 0x324e 0x25c2 0x25fe 0x2d2d 0x3102 0x322f 0x3224 0x25c0 0x25e0 0x2ce4 0x30ba 0x3144 0x306e 0x25bf 0x25d9 0x2c90 0x308e 0x3112 0x30f7 0x25bf 0x25cf 0x2c21 0x30bc 0x310b 0x303b 0x25bd 0x25c9 0x2b89 0x30a5 0x3139 0x3041 0x25bb 0x25c4 0x2abd 0x30c8 0x3142 0x2fd8 0x25b8 0x25bf 0x29b7 0x3048 0x30a9 0x2f80 0x25b6 0x25b9 0x2675 0x2fdb 0x3046 0x2f05 0x25b4 0x25b5 0x25d5 0x2f45 0x2f55 0x2eae 0x25b3 0x25b5 0x25bc 0x2e2d 0x2eb9 0x2d9f 0x25b3 0x25b5 0x25bc 0x2e2d 0x2eb9 0x2d9f 0x25b3 0x25b5 0x25bc 0x2e2d 0x2eb9 0x2d9f>;
	};

	qcom,pc-temp-y3-lut {
		qcom,lut-col-legend = <0xfffffff6 0x00 0x0a 0x19 0x28 0x32>;
		qcom,lut-row-legend = <0x2710 0x2648 0x2580 0x24b8 0x23f0 0x2328 0x2260 0x2198 0x20d0 0x2008 0x1f40 0x1e78 0x1db0 0x1ce8 0x1c20 0x1b58 0x1a90 0x19c8 0x1900 0x1838 0x1770 0x16a8 0x15e0 0x1518 0x1450 0x1388 0x12c0 0x11f8 0x1130 0x1068 0xfa0 0xed8 0xe10 0xd48 0xc80 0xbb8 0xaf0 0xa28 0x960 0x898 0x7d0 0x708 0x640 0x578 0x4b0 0x3e8 0x384 0x320 0x2bc 0x258 0x1f4 0x190 0x12c 0xc8 0x64 0x00>;
		qcom,lut-data = <0x343b 0x3407 0x33f2 0x33dd 0x33d3 0x33d2 0x3441 0x340b 0x33f2 0x33dd 0x33d3 0x33d2 0x3448 0x340f 0x33f2 0x33dd 0x33d4 0x33d3 0x344f 0x3413 0x33f2 0x33dd 0x33d5 0x33d3 0x3454 0x3416 0x33f2 0x33dd 0x33d5 0x33d4 0x3458 0x3418 0x33f2 0x33de 0x33d6 0x33d4 0x345b 0x3419 0x33f3 0x33de 0x33d6 0x33d5 0x345c 0x341a 0x33f5 0x33df 0x33d7 0x33d5 0x345f 0x341b 0x33f6 0x33df 0x33d7 0x33d5 0x3465 0x341d 0x33f7 0x33df 0x33d7 0x33d5 0x346a 0x341e 0x33f8 0x33df 0x33d7 0x33d6 0x3465 0x341f 0x33fa 0x33de 0x33d8 0x33d6 0x3457 0x3420 0x33fb 0x33dd 0x33da 0x33d5 0x344f 0x3420 0x33fc 0x33de 0x33db 0x33d6 0x344b 0x3420 0x33fe 0x33e1 0x33da 0x33d7 0x3448 0x341f 0x33fe 0x33e3 0x33da 0x33d9 0x3445 0x341c 0x33ff 0x33e4 0x33da 0x33d8 0x3441 0x3417 0x33ff 0x33e5 0x33db 0x33d8 0x343d 0x3413 0x33fe 0x33e6 0x33db 0x33d8 0x343a 0x3410 0x33fa 0x33e7 0x33dd 0x33da 0x3436 0x340d 0x33f6 0x33e8 0x33de 0x33db 0x3433 0x340a 0x33f3 0x33e4 0x33dc 0x33d9 0x3431 0x3406 0x33f1 0x33de 0x33d9 0x33d5 0x342d 0x3405 0x33ee 0x33dc 0x33d7 0x33d4 0x3425 0x3405 0x33eb 0x33dc 0x33d5 0x33d3 0x3419 0x3405 0x33ea 0x33dc 0x33d4 0x33d3 0x3411 0x3404 0x33eb 0x33db 0x33d4 0x33d3 0x3409 0x3402 0x33ec 0x33db 0x33d3 0x33d3 0x3405 0x33ff 0x33ed 0x33db 0x33d3 0x33d3 0x3407 0x33fd 0x33ee 0x33dd 0x33d4 0x33d3 0x340c 0x33fa 0x33ee 0x33de 0x33d5 0x33d4 0x3412 0x33f8 0x33ee 0x33de 0x33d6 0x33d4 0x341b 0x33f7 0x33ee 0x33de 0x33d6 0x33d3 0x3427 0x33f7 0x33ed 0x33dd 0x33d6 0x33d3 0x3434 0x33fc 0x33ec 0x33dd 0x33d6 0x33d3 0x3445 0x3403 0x33eb 0x33dd 0x33d6 0x33d3 0x345b 0x3406 0x33ec 0x33dd 0x33d6 0x33d3 0x3478 0x3409 0x33ee 0x33dc 0x33d5 0x33d2 0x349b 0x340b 0x33ef 0x33dc 0x33d5 0x33d2 0x34c5 0x340e 0x33f0 0x33db 0x33d4 0x33d2 0x34f8 0x3411 0x33f1 0x33db 0x33d4 0x33d2 0x3534 0x3415 0x33f3 0x33dc 0x33d4 0x33d2 0x357e 0x341a 0x33f4 0x33dc 0x33d3 0x33d2 0x35da 0x3424 0x33f6 0x33dc 0x33d3 0x33d2 0x3656 0x3437 0x33f8 0x33dc 0x33d4 0x33d2 0x3707 0x345d 0x33f9 0x33dd 0x33d6 0x33d3 0x375e 0x3478 0x33fb 0x33dc 0x33d5 0x33d5 0x378e 0x34ae 0x3401 0x33e0 0x33d8 0x33d6 0x3849 0x3504 0x3406 0x33e1 0x33da 0x33d8 0x3962 0x359d 0x3410 0x33e6 0x33dc 0x33d8 0x3c3f 0x36cb 0x3420 0x33e4 0x33d8 0x33d6 0x41e1 0x3a1b 0x3442 0x33e4 0x33d8 0x33d7 0x50d6 0x45ca 0x34dd 0x33e8 0x33da 0x33d8 0x82b8 0x75dc 0x3914 0x33ed 0x33dd 0x33db 0x82b8 0x75dc 0x3914 0x33ed 0x33dd 0x33db 0x82b8 0x75dc 0x3914 0x33ed 0x33dd 0x33db>;
	};

	qcom,pc-temp-y4-lut {
		qcom,lut-col-legend = <0xfffffff6 0x00 0x0a 0x19 0x28 0x32>;
		qcom,lut-row-legend = <0x2710 0x2648 0x2580 0x24b8 0x23f0 0x2328 0x2260 0x2198 0x20d0 0x2008 0x1f40 0x1e78 0x1db0 0x1ce8 0x1c20 0x1b58 0x1a90 0x19c8 0x1900 0x1838 0x1770 0x16a8 0x15e0 0x1518 0x1450 0x1388 0x12c0 0x11f8 0x1130 0x1068 0xfa0 0xed8 0xe10 0xd48 0xc80 0xbb8 0xaf0 0xa28 0x960 0x898 0x7d0 0x708 0x640 0x578 0x4b0 0x3e8 0x384 0x320 0x2bc 0x258 0x1f4 0x190 0x12c 0xc8 0x64 0x00>;
		qcom,lut-data = <0x411f 0x40c5 0x4077 0x4041 0x4034 0x4031 0x4140 0x40cc 0x407a 0x4042 0x4033 0x402e 0x416a 0x40d3 0x407d 0x4044 0x4032 0x402d 0x4195 0x40d9 0x4080 0x4045 0x4032 0x402c 0x41ba 0x40df 0x4083 0x4047 0x4032 0x402c 0x41d0 0x40e5 0x4085 0x4048 0x4032 0x402c 0x41d9 0x40e9 0x4087 0x404a 0x4032 0x402c 0x41de 0x40ed 0x4089 0x404c 0x4034 0x402d 0x41df 0x40f4 0x408c 0x404f 0x4037 0x402e 0x41d6 0x40ff 0x4092 0x4053 0x403a 0x4031 0x41cf 0x410a 0x4098 0x4059 0x403d 0x4033 0x41e7 0x4113 0x40a1 0x4060 0x403f 0x4036 0x4224 0x411c 0x40ab 0x4068 0x4041 0x403a 0x423a 0x412c 0x40ba 0x406d 0x4044 0x403c 0x420f 0x414a 0x40ce 0x4070 0x404a 0x403e 0x41d3 0x415e 0x40e0 0x4075 0x4051 0x4041 0x41aa 0x4148 0x40ed 0x407e 0x4057 0x4046 0x4186 0x4118 0x40f7 0x408d 0x405e 0x404d 0x416b 0x40f8 0x40f2 0x409c 0x4068 0x4055 0x4159 0x40e3 0x40ce 0x40b1 0x4077 0x4060 0x4149 0x40d2 0x40a8 0x40bb 0x407f 0x4065 0x4137 0x40c2 0x408c 0x4098 0x406b 0x4058 0x4123 0x40b3 0x4076 0x405f 0x404b 0x4041 0x4111 0x40a9 0x406f 0x404d 0x403f 0x4037 0x40ff 0x40a3 0x406c 0x4047 0x4039 0x4033 0x40f0 0x409d 0x406a 0x4045 0x4036 0x4031 0x40f0 0x4098 0x4069 0x4046 0x4038 0x4032 0x40fd 0x4094 0x4069 0x404a 0x403b 0x4034 0x410c 0x4090 0x4069 0x404d 0x403f 0x4037 0x4117 0x4089 0x406b 0x4050 0x4043 0x403b 0x4125 0x4084 0x406c 0x4055 0x4048 0x4040 0x412e 0x4085 0x406c 0x405a 0x404f 0x4046 0x4133 0x408b 0x406c 0x405f 0x4057 0x404d 0x4138 0x4091 0x406a 0x4063 0x405a 0x404f 0x413e 0x4097 0x4066 0x4066 0x405b 0x404f 0x4144 0x409f 0x4063 0x4067 0x405c 0x4050 0x4148 0x40ad 0x4067 0x405e 0x4052 0x4048 0x4149 0x40c0 0x406f 0x404f 0x4043 0x403c 0x414a 0x40d0 0x4076 0x404a 0x403e 0x4039 0x414b 0x40de 0x407d 0x4047 0x403d 0x4039 0x414d 0x40e8 0x4083 0x4046 0x403b 0x4039 0x414f 0x40e9 0x4089 0x4046 0x403a 0x4037 0x4157 0x40e6 0x408d 0x4046 0x4038 0x4035 0x4164 0x40e5 0x408d 0x4047 0x4035 0x4030 0x4177 0x40ea 0x4090 0x4044 0x4031 0x402d 0x418f 0x40fa 0x408d 0x4045 0x4034 0x4031 0x4196 0x4101 0x409a 0x4051 0x403d 0x4035 0x4182 0x4117 0x40ae 0x405a 0x4042 0x403e 0x4190 0x4137 0x40ce 0x4068 0x404d 0x404c 0x41a8 0x415e 0x40f6 0x4076 0x4057 0x4052 0x423a 0x417d 0x410c 0x4067 0x403e 0x4034 0x4357 0x41e4 0x4129 0x4061 0x4036 0x402f 0x466e 0x464b 0x4176 0x406b 0x4038 0x4032 0x54c2 0x7f88 0x42fe 0x408a 0x4045 0x4040 0x54c2 0x7f88 0x42fe 0x408a 0x4045 0x4040 0x54c2 0x7f88 0x42fe 0x408a 0x4045 0x4040>;
	};

	qcom,pc-temp-y5-lut {
		qcom,lut-col-legend = <0xfffffff6 0x00 0x0a 0x19 0x28 0x32>;
		qcom,lut-row-legend = <0x2710 0x2648 0x2580 0x24b8 0x23f0 0x2328 0x2260 0x2198 0x20d0 0x2008 0x1f40 0x1e78 0x1db0 0x1ce8 0x1c20 0x1b58 0x1a90 0x19c8 0x1900 0x1838 0x1770 0x16a8 0x15e0 0x1518 0x1450 0x1388 0x12c0 0x11f8 0x1130 0x1068 0xfa0 0xed8 0xe10 0xd48 0xc80 0xbb8 0xaf0 0xa28 0x960 0x898 0x7d0 0x708 0x640 0x578 0x4b0 0x3e8 0x384 0x320 0x2bc 0x258 0x1f4 0x190 0x12c 0xc8 0x64 0x00>;
		qcom,lut-data = <0x45ad 0x4d5a 0x5467 0x5459 0x4c90 0x518f 0x4775 0x4dee 0x5152 0x51b7 0x4df4 0x544d 0x495b 0x4e31 0x4dd4 0x4e9f 0x4eac 0x55f2 0x4b2e 0x4e33 0x4a69 0x4b88 0x4ee3 0x56bb 0x4cbc 0x4e06 0x478d 0x48ec 0x4ec1 0x56e3 0x4dd3 0x4dbc 0x45bd 0x4742 0x4e72 0x56a9 0x4e5c 0x4c87 0x44d5 0x4643 0x4d6a 0x55cc 0x4ebc 0x4ab0 0x4435 0x452d 0x4b8f 0x544c 0x4fdd 0x49e5 0x4394 0x43ae 0x4946 0x5281 0x54c1 0x4982 0x42bd 0x418b 0x45f1 0x4fc3 0x58ec 0x4953 0x4253 0x3f4c 0x442d 0x4ccc 0x55f6 0x4992 0x4263 0x3cb1 0x46da 0x4955 0x4e1e 0x4a49 0x4277 0x3a6b 0x4ae9 0x4641 0x4b71 0x4b8c 0x42a7 0x3a97 0x4ac6 0x4660 0x538a 0x4f6a 0x4377 0x3d87 0x4630 0x49d5 0x5c48 0x53bf 0x44df 0x3fcc 0x42d3 0x4c16 0x5c56 0x5769 0x4ca4 0x403e 0x4247 0x49cc 0x59cf 0x5aad 0x5820 0x4092 0x4256 0x462b 0x5862 0x5bd4 0x5c84 0x433f 0x437a 0x45e2 0x58aa 0x5c16 0x5e97 0x4e00 0x473a 0x48b4 0x5936 0x5bf2 0x5f8a 0x54cd 0x4c2a 0x4beb 0x5963 0x5acf 0x5efe 0x5458 0x545b 0x4f61 0x59ba 0x5908 0x5d76 0x53a6 0x5ca2 0x52e9 0x59d0 0x58d7 0x5aba 0x5399 0x5cd4 0x5429 0x538b 0x5b8d 0x5416 0x53fd 0x56b4 0x54a2 0x482d 0x5dd7 0x5011 0x5450 0x50ec 0x54a8 0x4061 0x5cfe 0x5418 0x53c6 0x4d42 0x535f 0x39c4 0x5a67 0x5a80 0x52d7 0x4aa0 0x518b 0x35a2 0x5781 0x5d94 0x5464 0x4b00 0x5128 0x3466 0x5374 0x62b6 0x5ce7 0x4f16 0x51f8 0x33c7 0x4f0e 0x66a6 0x6265 0x52ff 0x5252 0x33f8 0x4ab2 0x6803 0x6228 0x552f 0x5192 0x34d9 0x466b 0x68f5 0x61c2 0x573d 0x50be 0x35b5 0x45cc 0x67c0 0x6211 0x5a01 0x515e 0x3626 0x4e08 0x6095 0x6438 0x5e4f 0x5595 0x3684 0x5647 0x5be5 0x65a7 0x6098 0x5863 0x36cd 0x576f 0x5de2 0x6551 0x6085 0x56ca 0x372b 0x57d6 0x6119 0x6476 0x6047 0x53e2 0x3768 0x585f 0x6173 0x6287 0x5f73 0x5265 0x3716 0x5947 0x5f6a 0x5d3a 0x5d06 0x5110 0x362a 0x5a29 0x5d6c 0x594b 0x5b13 0x5077 0x3552 0x56f9 0x59ea 0x5aa7 0x5648 0x50d3 0x3499 0x4f71 0x56b2 0x5c4f 0x51a9 0x5191 0x3441 0x45d7 0x56aa 0x5742 0x5562 0x56b0 0x34d9 0x39c6 0x53a2 0x592c 0x5844 0x591a 0x35b4 0x37ee 0x5202 0x574e 0x55b0 0x5238 0x3620 0x3828 0x4ebb 0x4d1b 0x48d0 0x524a 0x35a5 0x37f6 0x4d86 0x51fe 0x530d 0x527a 0x3669 0x37cb 0x492b 0x4cb1 0x53e0 0x53bf 0x35eb 0x37ed 0x46d0 0x530b 0x5561 0x506e 0x332b 0x38b1 0x49b9 0x5487 0x4db7 0x5310 0x2d7b 0x35fd 0x3e80 0x57c5 0x503a 0x59d7 0x281e 0x292e 0x37fd 0x5cb5 0x5903 0x60ef 0x24a5 0x238a 0x306a 0x6078 0x6e7d 0x76e1 0x24a5 0x238a 0x306a 0x6078 0x6e7d 0x76e1 0x24a5 0x238a 0x306a 0x6078 0x6e7d 0x76e1>;
	};

	qcom,pc-temp-y6-lut {
		qcom,lut-col-legend = <0xfffffff6 0x00 0x0a 0x19 0x28 0x32>;
		qcom,lut-row-legend = <0x2710 0x2648 0x2580 0x24b8 0x23f0 0x2328 0x2260 0x2198 0x20d0 0x2008 0x1f40 0x1e78 0x1db0 0x1ce8 0x1c20 0x1b58 0x1a90 0x19c8 0x1900 0x1838 0x1770 0x16a8 0x15e0 0x1518 0x1450 0x1388 0x12c0 0x11f8 0x1130 0x1068 0xfa0 0xed8 0xe10 0xd48 0xc80 0xbb8 0xaf0 0xa28 0x960 0x898 0x7d0 0x708 0x640 0x578 0x4b0 0x3e8 0x384 0x320 0x2bc 0x258 0x1f4 0x190 0x12c 0xc8 0x64 0x00>;
		qcom,lut-data = <0x1544 0x1430 0x13be 0x1376 0x1363 0x1360 0x1548 0x1431 0x13bd 0x1376 0x1363 0x1360 0x1551 0x1433 0x13bc 0x1377 0x1363 0x1360 0x155b 0x1435 0x13bc 0x1377 0x1363 0x1360 0x1564 0x1437 0x13bc 0x1378 0x1364 0x1360 0x1568 0x1438 0x13bc 0x1378 0x1364 0x1361 0x1568 0x1438 0x13bc 0x1379 0x1365 0x1361 0x1567 0x1438 0x13bd 0x137a 0x1366 0x1362 0x1566 0x1439 0x13be 0x137b 0x1366 0x1362 0x1565 0x143b 0x13bf 0x137c 0x1367 0x1363 0x1564 0x143e 0x13c2 0x137d 0x1368 0x1364 0x1566 0x1441 0x13c4 0x137f 0x136a 0x1365 0x156b 0x1443 0x13c8 0x1381 0x136c 0x1366 0x156d 0x1447 0x13cd 0x1383 0x136d 0x1367 0x1560 0x144f 0x13d3 0x1386 0x136f 0x1369 0x154d 0x1454 0x13d8 0x1389 0x1370 0x136b 0x1541 0x144c 0x13dc 0x138d 0x1372 0x136c 0x1536 0x143b 0x13df 0x1391 0x1375 0x136e 0x152e 0x142f 0x13dd 0x1396 0x1378 0x1370 0x1529 0x1428 0x13cf 0x139c 0x137e 0x1374 0x1525 0x1421 0x13c2 0x13a0 0x1381 0x1376 0x1522 0x141b 0x13b8 0x1393 0x137a 0x1371 0x1520 0x1415 0x13b1 0x137f 0x136e 0x1368 0x151e 0x1414 0x13ad 0x1379 0x1368 0x1364 0x1519 0x1414 0x13ab 0x1377 0x1365 0x1362 0x1514 0x1414 0x13aa 0x1376 0x1364 0x1361 0x1514 0x1414 0x13aa 0x1376 0x1365 0x1362 0x1519 0x1413 0x13ac 0x1377 0x1365 0x1362 0x1520 0x1413 0x13ad 0x1379 0x1367 0x1363 0x152b 0x1412 0x13af 0x137b 0x1368 0x1365 0x153b 0x1412 0x13b1 0x137d 0x136b 0x1366 0x154d 0x1413 0x13b2 0x137f 0x136d 0x1368 0x1561 0x1417 0x13b2 0x1381 0x1370 0x136a 0x1579 0x141c 0x13b2 0x1382 0x1371 0x136b 0x1593 0x1426 0x13b2 0x1383 0x1371 0x136b 0x15b0 0x1432 0x13b1 0x1384 0x1371 0x136b 0x15d1 0x1440 0x13b4 0x1381 0x136f 0x1369 0x15f5 0x1450 0x13b9 0x137d 0x136a 0x1365 0x161c 0x1462 0x13be 0x137b 0x1369 0x1364 0x1647 0x1477 0x13c2 0x137b 0x1368 0x1364 0x1677 0x148d 0x13c7 0x137a 0x1368 0x1364 0x16ad 0x14a3 0x13cd 0x137b 0x1367 0x1364 0x16ed 0x14b9 0x13d3 0x137c 0x1366 0x1363 0x173c 0x14d6 0x13da 0x137c 0x1365 0x1362 0x17a8 0x1500 0x13e4 0x137c 0x1365 0x1361 0x183e 0x1540 0x13e7 0x137d 0x1367 0x1364 0x1886 0x1563 0x13f2 0x1380 0x1369 0x1366 0x18ad 0x15a6 0x1405 0x1386 0x136d 0x136a 0x1944 0x1604 0x141f 0x138b 0x1372 0x136f 0x1a2d 0x1696 0x1447 0x1393 0x1376 0x1371 0x1ca4 0x1799 0x147b 0x138e 0x136b 0x1367 0x2146 0x1a52 0x14c9 0x138d 0x136a 0x1366 0x2cdc 0x2428 0x15a3 0x1394 0x136c 0x1368 0x52ee 0x555c 0x1986 0x13a3 0x1373 0x136f 0x52ee 0x555c 0x1986 0x13a3 0x1373 0x136f 0x52ee 0x555c 0x1986 0x13a3 0x1373 0x136f>;
	};
};
